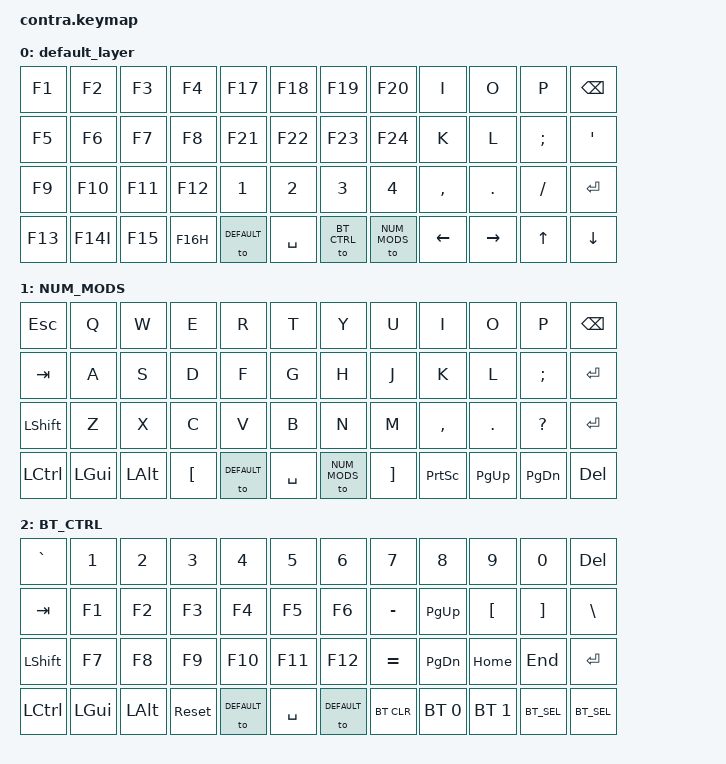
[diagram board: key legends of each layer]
/*
 * Copyright (c) 2021 The ZMK Contributors
 *
 * SPDX-License-Identifier: MIT
 */

#include <behaviors.dtsi>
#include <dt-bindings/zmk/keys.h>
#include <dt-bindings/zmk/bt.h>

#define DEFAULT  0
#define NUM_MODS 1
#define BT_CTRL  2

/ {
    keymap {
        compatible = "zmk,keymap";

        default_layer {
            bindings = <
    &kp F1   &kp F2     &kp F3    &kp F4     &kp F17       &kp F18      &kp F19     &kp F20        &kp I     &kp O     &kp P    &kp BSPC
    &kp F5   &kp F6     &kp F7    &kp F8     &kp F21       &kp F22      &kp F23     &kp F24        &kp K     &kp L     &kp SEMI &kp SQT
    &kp F9 &kp F10     &kp F11    &kp F12     &kp N1       &kp N2      &kp N3     &kp N4        &kp COMMA &kp DOT   &kp FSLH &kp ENTER
    &kp F13 &kp F14I  &kp F15 &kp F16H  &to DEFAULT &kp SPACE  &to BT_CTRL    &to NUM_MODS &kp LEFT  &kp RIGHT &kp UP   &kp DOWN
            >;
        };

        NUM_MODS {
            bindings = <
    &kp ESC &kp Q    &kp W   &kp E   &kp R      &kp T     &kp Y    &kp U      &kp I    &kp O    &kp P   &kp BSPC 
    &kp TAB   &kp A    &kp S   &kp D   &kp F      &kp G     &kp H    &kp J   &kp K &kp L  &kp SEMI &kp ENTER
    &kp LSHFT &kp Z    &kp X   &kp C   &kp V     &kp B    &kp N   &kp M   &kp COMMA &kp DOT  &kp QUESTION  &kp ENTER
    &kp LCTRL &kp LGUI  &kp LALT &kp LBKT   &to DEFAULT &kp SPACE  &to NUM_MODS    &kp RBKT &kp PSCRN   &kp PG_UP &kp PG_DN   &kp DEL
            >;
        };

        BT_CTRL {
            bindings = <
    &kp GRAVE &kp N1    &kp N2   &kp N3   &kp N4      &kp N5     &kp N6    &kp N7      &kp N8    &kp N9    &kp N0   &kp DEL
    &kp TAB   &kp F1    &kp F2   &kp F3   &kp F4      &kp F5     &kp F6    &kp MINUS   &kp PG_UP &kp LBKT  &kp RBKT &kp BSLH
    &kp LSHFT &kp F7    &kp F8   &kp F9   &kp F10     &kp F11    &kp F12   &kp EQUAL   &kp PG_DN &kp HOME  &kp END  &kp ENTER
    &kp LCTRL &kp LGUI  &kp LALT &sys_reset   &to DEFAULT &kp SPACE  &to DEFAULT    &bt BT_CLR &bt BT_SEL 0  &bt BT_SEL 1 &kp BT_SEL 2   &kp BT_SEL 3
            >;
        };
    };
};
